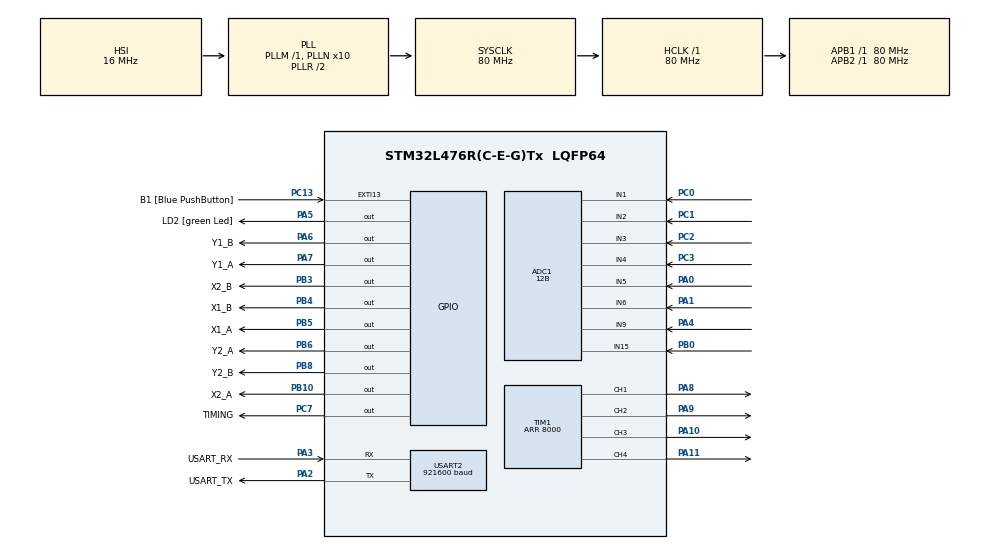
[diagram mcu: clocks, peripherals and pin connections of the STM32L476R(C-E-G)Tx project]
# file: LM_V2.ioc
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ADC1.Channel-0\#ChannelRegularConversion=ADC_CHANNEL_15
ADC1.Channel-1\#ChannelRegularConversion=ADC_CHANNEL_2
ADC1.Channel-2\#ChannelRegularConversion=ADC_CHANNEL_1
ADC1.Channel-3\#ChannelRegularConversion=ADC_CHANNEL_3
ADC1.Channel-4\#ChannelRegularConversion=ADC_CHANNEL_5
ADC1.Channel-5\#ChannelRegularConversion=ADC_CHANNEL_6
ADC1.Channel-6\#ChannelRegularConversion=ADC_CHANNEL_9
ADC1.Channel-7\#ChannelRegularConversion=ADC_CHANNEL_4
ADC1.ClockPrescaler=ADC_CLOCK_SYNC_PCLK_DIV4
ADC1.ContinuousConvMode=DISABLE
ADC1.DMAContinuousRequests=ENABLE
ADC1.DataAlign=ADC_DATAALIGN_RIGHT
ADC1.DiscontinuousConvMode=DISABLE
ADC1.EOCSelection=ADC_EOC_SEQ_CONV
ADC1.ExternalTrigConv=ADC_EXTERNALTRIG_T1_TRGO
ADC1.ExternalTrigConvEdge=ADC_EXTERNALTRIGCONVEDGE_RISING
ADC1.LowPowerAutoWait=DISABLE
ADC1.NbrOfConversion=8
ADC1.NbrOfConversionFlag=1
ADC1.OffsetNumber-0\#ChannelRegularConversion=ADC_OFFSET_NONE
ADC1.OffsetNumber-1\#ChannelRegularConversion=ADC_OFFSET_NONE
ADC1.OffsetNumber-2\#ChannelRegularConversion=ADC_OFFSET_NONE
ADC1.OffsetNumber-3\#ChannelRegularConversion=ADC_OFFSET_NONE
ADC1.OffsetNumber-4\#ChannelRegularConversion=ADC_OFFSET_NONE
ADC1.OffsetNumber-5\#ChannelRegularConversion=ADC_OFFSET_NONE
ADC1.OffsetNumber-6\#ChannelRegularConversion=ADC_OFFSET_NONE
ADC1.OffsetNumber-7\#ChannelRegularConversion=ADC_OFFSET_NONE
ADC1.Overrun=ADC_OVR_DATA_OVERWRITTEN
ADC1.OversamplingMode=ENABLE
ADC1.OversamplingStopReset=ADC_REGOVERSAMPLING_CONTINUED_MODE
ADC1.Rank-0\#ChannelRegularConversion=1
ADC1.Rank-1\#ChannelRegularConversion=2
ADC1.Rank-2\#ChannelRegularConversion=3
ADC1.Rank-3\#ChannelRegularConversion=4
ADC1.Rank-4\#ChannelRegularConversion=5
ADC1.Rank-5\#ChannelRegularConversion=6
ADC1.Rank-6\#ChannelRegularConversion=7
ADC1.Rank-7\#ChannelRegularConversion=8
ADC1.Ratio=ADC_OVERSAMPLING_RATIO_4
ADC1.Resolution=ADC_RESOLUTION_12B
ADC1.RightBitShift=ADC_RIGHTBITSHIFT_2
ADC1.SamplingTime-0\#ChannelRegularConversion=ADC_SAMPLETIME_24CYCLES_5
ADC1.SamplingTime-1\#ChannelRegularConversion=ADC_SAMPLETIME_24CYCLES_5
ADC1.SamplingTime-2\#ChannelRegularConversion=ADC_SAMPLETIME_24CYCLES_5
ADC1.SamplingTime-3\#ChannelRegularConversion=ADC_SAMPLETIME_24CYCLES_5
ADC1.SamplingTime-4\#ChannelRegularConversion=ADC_SAMPLETIME_24CYCLES_5
ADC1.SamplingTime-5\#ChannelRegularConversion=ADC_SAMPLETIME_24CYCLES_5
ADC1.SamplingTime-6\#ChannelRegularConversion=ADC_SAMPLETIME_24CYCLES_5
ADC1.SamplingTime-7\#ChannelRegularConversion=ADC_SAMPLETIME_24CYCLES_5
ADC1.TriggeredMode=ADC_TRIGGEREDMODE_SINGLE_TRIGGER
ADC1.master=1
Dma.ADC1.0.Direction=DMA_PERIPH_TO_MEMORY
Dma.ADC1.0.Instance=DMA1_Channel1
Dma.ADC1.0.MemDataAlignment=DMA_MDATAALIGN_HALFWORD
Dma.ADC1.0.MemInc=DMA_MINC_ENABLE
Dma.ADC1.0.Mode=DMA_CIRCULAR
Dma.ADC1.0.PeriphDataAlignment=DMA_PDATAALIGN_HALFWORD
Dma.ADC1.0.PeriphInc=DMA_PINC_DISABLE
Dma.ADC1.0.Priority=DMA_PRIORITY_HIGH
Dma.Request0=ADC1
Mcu.Family=STM32L4
Mcu.Name=STM32L476R(C-E-G)Tx
Mcu.Package=LQFP64
NVIC.DMA1_Channel1_IRQn=true\:0\:0\:false\:false\:true\:false\:true\:true
NVIC.EXTI15_10_IRQn=true\:0\:0\:false\:false\:true\:true\:true\:true
NVIC.PriorityGroup=NVIC_PRIORITYGROUP_4
PA0.Signal=ADCx_IN5
PA1.Signal=ADCx_IN6
PA10.Signal=S_TIM1_CH3
PA11.Signal=S_TIM1_CH4
PA13\ (JTMS-SWDIO).GPIO_Label=TMS
PA13\ (JTMS-SWDIO).Mode=Serial_Wire
PA13\ (JTMS-SWDIO).Signal=SYS_JTMS-SWDIO
PA14\ (JTCK-SWCLK).GPIO_Label=TCK
PA14\ (JTCK-SWCLK).Mode=Serial_Wire
PA14\ (JTCK-SWCLK).Signal=SYS_JTCK-SWCLK
PA2.GPIO_Label=USART_TX
PA2.GPIO_Mode=GPIO_MODE_AF_PP
PA2.GPIO_PuPd=GPIO_NOPULL
PA2.GPIO_Speed=GPIO_SPEED_FREQ_VERY_HIGH
PA2.Mode=Asynchronous
PA2.Signal=USART2_TX
PA3.GPIO_Label=USART_RX
PA3.GPIO_Mode=GPIO_MODE_AF_PP
PA3.GPIO_PuPd=GPIO_NOPULL
PA3.GPIO_Speed=GPIO_SPEED_FREQ_VERY_HIGH
PA3.Mode=Asynchronous
PA3.Signal=USART2_RX
PA4.Signal=ADCx_IN9
PA5.GPIO_Label=LD2 [green Led]
PA5.GPIO_ModeDefaultOutputPP=GPIO_MODE_OUTPUT_PP
PA5.GPIO_PuPd=GPIO_NOPULL
PA5.GPIO_Speed=GPIO_SPEED_FREQ_LOW
PA5.Signal=GPIO_Output
PA6.GPIO_Label=Y1_B
PA6.Signal=GPIO_Output
PA7.GPIO_Label=Y1_A
PA7.Signal=GPIO_Output
PA8.Signal=S_TIM1_CH1
PA9.Signal=S_TIM1_CH2
PB0.Signal=ADCx_IN15
PB10.GPIO_Label=X2_A
PB10.Signal=GPIO_Output
PB3\ (JTDO-TRACESWO).GPIO_Label=X2_B
PB3\ (JTDO-TRACESWO).Signal=GPIO_Output
PB4\ (NJTRST).GPIO_Label=X1_B
PB4\ (NJTRST).Signal=GPIO_Output
PB5.GPIO_Label=X1_A
PB5.Signal=GPIO_Output
PB6.GPIO_Label=Y2_A
PB6.Signal=GPIO_Output
PB8.GPIO_Label=Y2_B
PB8.Signal=GPIO_Output
PC0.Signal=ADCx_IN1
PC1.Signal=ADCx_IN2
PC13.GPIO_Label=B1 [Blue PushButton]
PC13.GPIO_ModeDefaultEXTI=GPIO_MODE_IT_FALLING
PC13.GPIO_PuPd=GPIO_NOPULL
PC13.Signal=GPXTI13
PC14-OSC32_IN\ (PC14).Mode=LSE-External-Oscillator
PC14-OSC32_IN\ (PC14).Signal=RCC_OSC32_IN
PC15-OSC32_OUT\ (PC15).Mode=LSE-External-Oscillator
PC15-OSC32_OUT\ (PC15).Signal=RCC_OSC32_OUT
PC2.Signal=ADCx_IN3
PC3.Signal=ADCx_IN4
PC7.GPIO_Label=TIMING
PC7.Signal=GPIO_Output
PH0-OSC_IN\ (PH0).Signal=RCC_OSC_IN
PH1-OSC_OUT\ (PH1).Signal=RCC_OSC_OUT
ProjectManager.HeapSize=0x200
ProjectManager.StackSize=0x400
ProjectManager.TargetToolchain=STM32CubeIDE
RCC.ADCFreq_Value=64000000
RCC.AHBFreq_Value=80000000
RCC.APB1Freq_Value=80000000
RCC.APB1TimFreq_Value=80000000
RCC.APB2Freq_Value=80000000
RCC.APB2TimFreq_Value=80000000
RCC.CortexFreq_Value=80000000
RCC.HCLKFreq_Value=80000000
RCC.HSE_VALUE=8000000
RCC.HSI_VALUE=16000000
RCC.MSI_VALUE=4000000
RCC.PLLN=10
RCC.PLLSourceVirtual=RCC_PLLSOURCE_HSI
RCC.PREFETCH_ENABLE=1
RCC.SYSCLKFreq_VALUE=80000000
RCC.SYSCLKSource=RCC_SYSCLKSOURCE_PLLCLK
RCC.USBFreq_Value=64000000
RCC.VCOOutputFreq_Value=160000000
SH.ADCx_IN1.0=ADC1_IN1,IN1-Single-Ended
SH.ADCx_IN15.0=ADC1_IN15,IN15-Single-Ended
SH.ADCx_IN2.0=ADC1_IN2,IN2-Single-Ended
SH.ADCx_IN3.0=ADC1_IN3,IN3-Single-Ended
SH.ADCx_IN4.0=ADC1_IN4,IN4-Single-Ended
SH.ADCx_IN5.0=ADC1_IN5,IN5-Single-Ended
SH.ADCx_IN6.0=ADC1_IN6,IN6-Single-Ended
SH.ADCx_IN9.0=ADC1_IN9,IN9-Single-Ended
SH.S_TIM1_CH1.0=TIM1_CH1,PWM Generation1 CH1
SH.S_TIM1_CH2.0=TIM1_CH2,PWM Generation2 CH2
SH.S_TIM1_CH3.0=TIM1_CH3,PWM Generation3 CH3
SH.S_TIM1_CH4.0=TIM1_CH4,PWM Generation4 CH4
TIM1.AutoReloadPreload=TIM_AUTORELOAD_PRELOAD_ENABLE
TIM1.Channel-PWM\ Generation1\ CH1=TIM_CHANNEL_1
TIM1.Channel-PWM\ Generation2\ CH2=TIM_CHANNEL_2
TIM1.Channel-PWM\ Generation3\ CH3=TIM_CHANNEL_3
TIM1.Channel-PWM\ Generation4\ CH4=TIM_CHANNEL_4
TIM1.CounterMode=TIM_COUNTERMODE_CENTERALIGNED1
TIM1.Period=8000
TIM1.RepetitionCounter=1
TIM1.TIM_MasterOutputTrigger=TIM_TRGO_UPDATE
USART2.BaudRate=921600
USART2.VirtualMode-Asynchronous=VM_ASYNC
VP_TIM1_VS_ClockSourceINT.Mode=Internal
board=NUCLEO-L476RG

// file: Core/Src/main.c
/* USER CODE BEGIN Header */
/**
  ******************************************************************************
  * @file           : main.c
  * @brief          : Main program body
  ******************************************************************************
  * @attention
  *
  * Copyright (c) 2026 STMicroelectronics.
  * All rights reserved.
  *
  * This software is licensed under terms that can be found in the LICENSE file
  * in the root directory of this software component.
  * If no LICENSE file comes with this software, it is provided AS-IS.
  *
  ******************************************************************************
  */
/* USER CODE END Header */
#include "main.h"

/* USER CODE BEGIN Includes */
#include "LM.h"
/* USER CODE END Includes */

ADC_HandleTypeDef hadc1;
DMA_HandleTypeDef hdma_adc1;

TIM_HandleTypeDef htim1;

UART_HandleTypeDef huart2;

void SystemClock_Config(void);
static void MX_GPIO_Init(void);
static void MX_DMA_Init(void);
static void MX_USART2_UART_Init(void);
static void MX_ADC1_Init(void);
static void MX_TIM1_Init(void);

int main(void)
{

  /* MCU Configuration--------------------------------------------------------*/

  /* Reset of all peripherals, Initializes the Flash interface and the Systick. */
  HAL_Init();

  /* Configure the system clock */
  SystemClock_Config();

  /* Initialize all configured peripherals */
  MX_GPIO_Init();
  MX_DMA_Init();
  MX_USART2_UART_Init();
  MX_ADC1_Init();
  MX_TIM1_Init();
  /* USER CODE BEGIN 2 */
  LM_Init();    /* reglages + verification de la configuration CubeMX */
  LM_Start();   /* calibration ADC, DMA, PWM : la boucle tourne a 5 kHz sous interruption */
  /* USER CODE END 2 */

  /* Infinite loop */
  while (1)
  {

    /* USER CODE BEGIN 3 */
    LM_Background();   /* log serie + LED */
  }
  /* USER CODE END 3 */
}

void SystemClock_Config(void)
{
  RCC_OscInitTypeDef RCC_OscInitStruct = {0};
  RCC_ClkInitTypeDef RCC_ClkInitStruct = {0};

  /** Configure the main internal regulator output voltage
  */
  if (HAL_PWREx_ControlVoltageScaling(PWR_REGULATOR_VOLTAGE_SCALE1) != HAL_OK)
  {
    Error_Handler();
  }

  /** Initializes the RCC Oscillators according to the specified parameters
  * in the RCC_OscInitTypeDef structure.
  */
  RCC_OscInitStruct.OscillatorType = RCC_OSCILLATORTYPE_HSI;
  RCC_OscInitStruct.HSIState = RCC_HSI_ON;
  RCC_OscInitStruct.HSICalibrationValue = RCC_HSICALIBRATION_DEFAULT;
  RCC_OscInitStruct.PLL.PLLState = RCC_PLL_ON;
  RCC_OscInitStruct.PLL.PLLSource = RCC_PLLSOURCE_HSI;
  RCC_OscInitStruct.PLL.PLLM = 1;
  RCC_OscInitStruct.PLL.PLLN = 10;
  RCC_OscInitStruct.PLL.PLLP = RCC_PLLP_DIV7;
  RCC_OscInitStruct.PLL.PLLQ = RCC_PLLQ_DIV2;
  RCC_OscInitStruct.PLL.PLLR = RCC_PLLR_DIV2;
  if (HAL_RCC_OscConfig(&RCC_OscInitStruct) != HAL_OK)
  {
    Error_Handler();
  }

  /** Initializes the CPU, AHB and APB buses clocks
  */
  RCC_ClkInitStruct.ClockType = RCC_CLOCKTYPE_HCLK|RCC_CLOCKTYPE_SYSCLK
                              |RCC_CLOCKTYPE_PCLK1|RCC_CLOCKTYPE_PCLK2;
  RCC_ClkInitStruct.SYSCLKSource = RCC_SYSCLKSOURCE_PLLCLK;
  RCC_ClkInitStruct.AHBCLKDivider = RCC_SYSCLK_DIV1;
  RCC_ClkInitStruct.APB1CLKDivider = RCC_HCLK_DIV1;
  RCC_ClkInitStruct.APB2CLKDivider = RCC_HCLK_DIV1;

  if (HAL_RCC_ClockConfig(&RCC_ClkInitStruct, FLASH_LATENCY_4) != HAL_OK)
  {
    Error_Handler();
  }
}

static void MX_ADC1_Init(void)
{

  ADC_MultiModeTypeDef multimode = {0};
  ADC_ChannelConfTypeDef sConfig = {0};

  /** Common config
  */
  hadc1.Instance = ADC1;
  hadc1.Init.ClockPrescaler = ADC_CLOCK_SYNC_PCLK_DIV4;
  hadc1.Init.Resolution = ADC_RESOLUTION_12B;
  hadc1.Init.DataAlign = ADC_DATAALIGN_RIGHT;
  hadc1.Init.ScanConvMode = ADC_SCAN_ENABLE;
  hadc1.Init.EOCSelection = ADC_EOC_SEQ_CONV;
  hadc1.Init.LowPowerAutoWait = DISABLE;
  hadc1.Init.ContinuousConvMode = DISABLE;
  hadc1.Init.NbrOfConversion = 8;
  hadc1.Init.DiscontinuousConvMode = DISABLE;
  hadc1.Init.ExternalTrigConv = ADC_EXTERNALTRIG_T1_TRGO;
  hadc1.Init.ExternalTrigConvEdge = ADC_EXTERNALTRIGCONVEDGE_RISING;
  hadc1.Init.DMAContinuousRequests = ENABLE;
  hadc1.Init.Overrun = ADC_OVR_DATA_OVERWRITTEN;
  hadc1.Init.OversamplingMode = ENABLE;
  hadc1.Init.Oversampling.Ratio = ADC_OVERSAMPLING_RATIO_4;
  hadc1.Init.Oversampling.RightBitShift = ADC_RIGHTBITSHIFT_2;
  hadc1.Init.Oversampling.TriggeredMode = ADC_TRIGGEREDMODE_SINGLE_TRIGGER;
  hadc1.Init.Oversampling.OversamplingStopReset = ADC_REGOVERSAMPLING_CONTINUED_MODE;
  if (HAL_ADC_Init(&hadc1) != HAL_OK)
  {
    Error_Handler();
  }

  /** Configure the ADC multi-mode
  */
  multimode.Mode = ADC_MODE_INDEPENDENT;
  if (HAL_ADCEx_MultiModeConfigChannel(&hadc1, &multimode) != HAL_OK)
  {
    Error_Handler();
  }

  /** Configure Regular Channel : rang 1, I_X1 (PB0)
  */
  sConfig.Channel = ADC_CHANNEL_15;
  sConfig.Rank = ADC_REGULAR_RANK_1;
  sConfig.SamplingTime = ADC_SAMPLETIME_24CYCLES_5;
  sConfig.SingleDiff = ADC_SINGLE_ENDED;
  sConfig.OffsetNumber = ADC_OFFSET_NONE;
  sConfig.Offset = 0;
  if (HAL_ADC_ConfigChannel(&hadc1, &sConfig) != HAL_OK)
  {
    Error_Handler();
  }

  /** Configure Regular Channel : rang 2, I_X2 (PC1)
  */
  sConfig.Channel = ADC_CHANNEL_2;
  sConfig.Rank = ADC_REGULAR_RANK_2;
  if (HAL_ADC_ConfigChannel(&hadc1, &sConfig) != HAL_OK)
  {
    Error_Handler();
  }

  /** Configure Regular Channel : rang 3, I_Y1 (PC0)
  */
  sConfig.Channel = ADC_CHANNEL_1;
  sConfig.Rank = ADC_REGULAR_RANK_3;
  if (HAL_ADC_ConfigChannel(&hadc1, &sConfig) != HAL_OK)
  {
    Error_Handler();
  }

  /** Configure Regular Channel : rang 4, I_Y2 (PC2)
  */
  sConfig.Channel = ADC_CHANNEL_3;
  sConfig.Rank = ADC_REGULAR_RANK_4;
  if (HAL_ADC_ConfigChannel(&hadc1, &sConfig) != HAL_OK)
  {
    Error_Handler();
  }

  /** Configure Regular Channel : rang 5, HALL_1 (PA0)
  */
  sConfig.Channel = ADC_CHANNEL_5;
  sConfig.Rank = ADC_REGULAR_RANK_5;
  if (HAL_ADC_ConfigChannel(&hadc1, &sConfig) != HAL_OK)
  {
    Error_Handler();
  }

  /** Configure Regular Channel : rang 6, HALL_2 (PA1)
  */
  sConfig.Channel = ADC_CHANNEL_6;
  sConfig.Rank = ADC_REGULAR_RANK_6;
  if (HAL_ADC_ConfigChannel(&hadc1, &sConfig) != HAL_OK)
  {
    Error_Handler();
  }

  /** Configure Regular Channel : rang 7, HALL_3 (PA4)
  */
  sConfig.Channel = ADC_CHANNEL_9;
  sConfig.Rank = ADC_REGULAR_RANK_7;
  if (HAL_ADC_ConfigChannel(&hadc1, &sConfig) != HAL_OK)
  {
    Error_Handler();
  }

  /** Configure Regular Channel : rang 8, VBUS (PC3)
  */
  sConfig.Channel = ADC_CHANNEL_4;
  sConfig.Rank = ADC_REGULAR_RANK_8;
  if (HAL_ADC_ConfigChannel(&hadc1, &sConfig) != HAL_OK)
  {
    Error_Handler();
  }

}

static void MX_TIM1_Init(void)
{

  TIM_MasterConfigTypeDef sMasterConfig = {0};
  TIM_OC_InitTypeDef sConfigOC = {0};
  TIM_BreakDeadTimeConfigTypeDef sBreakDeadTimeConfig = {0};

  htim1.Instance = TIM1;
  htim1.Init.Prescaler = 0;
  htim1.Init.CounterMode = TIM_COUNTERMODE_CENTERALIGNED1;
  htim1.Init.Period = 8000;
  htim1.Init.ClockDivision = TIM_CLOCKDIVISION_DIV1;
  htim1.Init.RepetitionCounter = 1;
  htim1.Init.AutoReloadPreload = TIM_AUTORELOAD_PRELOAD_ENABLE;
  if (HAL_TIM_PWM_Init(&htim1) != HAL_OK)
  {
    Error_Handler();
  }
  sMasterConfig.MasterOutputTrigger = TIM_TRGO_UPDATE;
  sMasterConfig.MasterOutputTrigger2 = TIM_TRGO2_RESET;
  sMasterConfig.MasterSlaveMode = TIM_MASTERSLAVEMODE_DISABLE;
  if (HAL_TIMEx_MasterConfigSynchronization(&htim1, &sMasterConfig) != HAL_OK)
  {
    Error_Handler();
  }
  sConfigOC.OCMode = TIM_OCMODE_PWM1;
  sConfigOC.Pulse = 0;
  sConfigOC.OCPolarity = TIM_OCPOLARITY_HIGH;
  sConfigOC.OCNPolarity = TIM_OCNPOLARITY_HIGH;
  sConfigOC.OCFastMode = TIM_OCFAST_DISABLE;
  sConfigOC.OCIdleState = TIM_OCIDLESTATE_RESET;
  sConfigOC.OCNIdleState = TIM_OCNIDLESTATE_RESET;
  if (HAL_TIM_PWM_ConfigChannel(&htim1, &sConfigOC, TIM_CHANNEL_1) != HAL_OK)
  {
    Error_Handler();
  }
  if (HAL_TIM_PWM_ConfigChannel(&htim1, &sConfigOC, TIM_CHANNEL_2) != HAL_OK)
  {
    Error_Handler();
  }
  if (HAL_TIM_PWM_ConfigChannel(&htim1, &sConfigOC, TIM_CHANNEL_3) != HAL_OK)
  {
    Error_Handler();
  }
  if (HAL_TIM_PWM_ConfigChannel(&htim1, &sConfigOC, TIM_CHANNEL_4) != HAL_OK)
  {
    Error_Handler();
  }
  sBreakDeadTimeConfig.OffStateRunMode = TIM_OSSR_DISABLE;
  sBreakDeadTimeConfig.OffStateIDLEMode = TIM_OSSI_DISABLE;
  sBreakDeadTimeConfig.LockLevel = TIM_LOCKLEVEL_OFF;
  sBreakDeadTimeConfig.DeadTime = 0;
  sBreakDeadTimeConfig.BreakState = TIM_BREAK_DISABLE;
  sBreakDeadTimeConfig.BreakPolarity = TIM_BREAKPOLARITY_HIGH;
  sBreakDeadTimeConfig.BreakFilter = 0;
  sBreakDeadTimeConfig.Break2State = TIM_BREAK2_DISABLE;
  sBreakDeadTimeConfig.Break2Polarity = TIM_BREAK2POLARITY_HIGH;
  sBreakDeadTimeConfig.Break2Filter = 0;
  sBreakDeadTimeConfig.AutomaticOutput = TIM_AUTOMATICOUTPUT_DISABLE;
  if (HAL_TIMEx_ConfigBreakDeadTime(&htim1, &sBreakDeadTimeConfig) != HAL_OK)
  {
    Error_Handler();
  }
  HAL_TIM_MspPostInit(&htim1);

}

static void MX_USART2_UART_Init(void)
{

  huart2.Instance = USART2;
  huart2.Init.BaudRate = 921600;
  huart2.Init.WordLength = UART_WORDLENGTH_8B;
  huart2.Init.StopBits = UART_STOPBITS_1;
  huart2.Init.Parity = UART_PARITY_NONE;
  huart2.Init.Mode = UART_MODE_TX_RX;
  huart2.Init.HwFlowCtl = UART_HWCONTROL_NONE;
  huart2.Init.OverSampling = UART_OVERSAMPLING_16;
  huart2.Init.OneBitSampling = UART_ONE_BIT_SAMPLE_DISABLE;
  huart2.AdvancedInit.AdvFeatureInit = UART_ADVFEATURE_NO_INIT;
  if (HAL_UART_Init(&huart2) != HAL_OK)
  {
    Error_Handler();
  }

}

static void MX_DMA_Init(void)
{

  /* DMA controller clock enable */
  __HAL_RCC_DMA1_CLK_ENABLE();

  /* DMA interrupt init */
  /* DMA1_Channel1_IRQn interrupt configuration */
  HAL_NVIC_SetPriority(DMA1_Channel1_IRQn, 0, 0);
  HAL_NVIC_EnableIRQ(DMA1_Channel1_IRQn);

}

static void MX_GPIO_Init(void)
{
  GPIO_InitTypeDef GPIO_InitStruct = {0};

  /* GPIO Ports Clock Enable */
  __HAL_RCC_GPIOC_CLK_ENABLE();
  __HAL_RCC_GPIOH_CLK_ENABLE();
  __HAL_RCC_GPIOA_CLK_ENABLE();
  __HAL_RCC_GPIOB_CLK_ENABLE();

  /*Configure GPIO pin Output Level */
  HAL_GPIO_WritePin(GPIOA, LD2_Pin|Y1_B_Pin|Y1_A_Pin, GPIO_PIN_RESET);

  /*Configure GPIO pin Output Level */
  HAL_GPIO_WritePin(GPIOB, X2_A_Pin|X2_B_Pin|X1_B_Pin|X1_A_Pin
                          |Y2_A_Pin|Y2_B_Pin, GPIO_PIN_RESET);

  /*Configure GPIO pin Output Level */
  HAL_GPIO_WritePin(TIMING_GPIO_Port, TIMING_Pin, GPIO_PIN_RESET);

  /*Configure GPIO pin : B1_Pin */
  GPIO_InitStruct.Pin = B1_Pin;
  GPIO_InitStruct.Mode = GPIO_MODE_IT_FALLING;
  GPIO_InitStruct.Pull = GPIO_NOPULL;
  HAL_GPIO_Init(B1_GPIO_Port, &GPIO_InitStruct);

  /*Configure GPIO pins : LD2_Pin Y1_B_Pin Y1_A_Pin */
  GPIO_InitStruct.Pin = LD2_Pin|Y1_B_Pin|Y1_A_Pin;
  GPIO_InitStruct.Mode = GPIO_MODE_OUTPUT_PP;
  GPIO_InitStruct.Pull = GPIO_NOPULL;
  GPIO_InitStruct.Speed = GPIO_SPEED_FREQ_LOW;
  HAL_GPIO_Init(GPIOA, &GPIO_InitStruct);

  /*Configure GPIO pins : X2_A_Pin X2_B_Pin X1_B_Pin X1_A_Pin
                           Y2_A_Pin Y2_B_Pin */
  GPIO_InitStruct.Pin = X2_A_Pin|X2_B_Pin|X1_B_Pin|X1_A_Pin
                          |Y2_A_Pin|Y2_B_Pin;
  GPIO_InitStruct.Mode = GPIO_MODE_OUTPUT_PP;
  GPIO_InitStruct.Pull = GPIO_NOPULL;
  GPIO_InitStruct.Speed = GPIO_SPEED_FREQ_LOW;
  HAL_GPIO_Init(GPIOB, &GPIO_InitStruct);

  /*Configure GPIO pin : TIMING_Pin */
  GPIO_InitStruct.Pin = TIMING_Pin;
  GPIO_InitStruct.Mode = GPIO_MODE_OUTPUT_PP;
  GPIO_InitStruct.Pull = GPIO_NOPULL;
  GPIO_InitStruct.Speed = GPIO_SPEED_FREQ_LOW;
  HAL_GPIO_Init(TIMING_GPIO_Port, &GPIO_InitStruct);

  /* EXTI interrupt init*/
  HAL_NVIC_SetPriority(EXTI15_10_IRQn, 0, 0);
  HAL_NVIC_EnableIRQ(EXTI15_10_IRQn);

}

void Error_Handler(void)
{
  /* USER CODE BEGIN Error_Handler_Debug */
  /* Erreur de configuration : on coupe les ponts et on s'arrete (LED LD2 eteinte). */
  __disable_irq();
  if (htim1.Instance != NULL)
  {
    __HAL_TIM_MOE_DISABLE_UNCONDITIONALLY(&htim1);
  }
  while (1)
  {
  }
  /* USER CODE END Error_Handler_Debug */
}
